# D1H.pdf register map
Vendor: Allwinner; Series: D1H.pdf; File version: 0.1
CPU: XuanTie C906 RISC-V CPU 0, little endian, MPU, FPU, double-precision FPU, 0 interrupt priority bits
Registers are 32-bit, read-write, reset 0x0 unless marked. A register's access mark holds for its fields unless they carry their own. Offsets are from the block's base; [hi:lo] are bit positions.

## USB1 (part 2 of 2)
Base 0x04200000
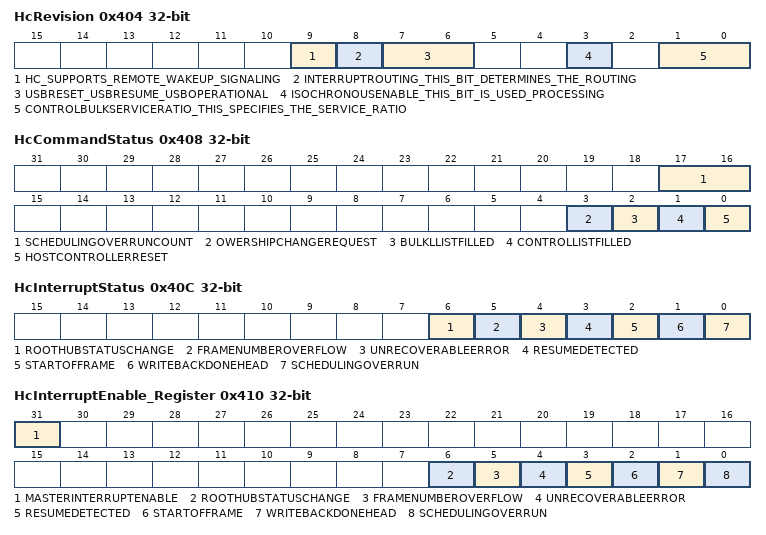
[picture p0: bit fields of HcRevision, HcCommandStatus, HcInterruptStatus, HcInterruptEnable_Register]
0x404 HcRevision (reset mask 0x53F)
  [9] HC_SUPPORTS_REMOTE_WAKEUP_SIGNALING — This bit indicates whether HC supports remote wakeup signaling. If remote wakeup is supported and used by the system, it is the responsibility of system firmware to set this bit during POST. HC clear the bit upon a hardware reset but does not alter it upon a software reset. Remote wakeup signaling of the host system is host-bus-specific and is not described in this specification.
  [8] INTERRUPTROUTING_THIS_BIT_DETERMINES_THE_ROUTING — InterruptRouting This bit determines the routing of interrupts generated by events registered in HcInterruptStatus. If clear, all interrupt are routed to the normal host bus interrupt mechanism. If set interrupts are routed to the System Management Interrupt. HCD clears this bit upon a hardware reset, but it does not alter this bit upon a software reset. HCD uses this bit as a tag to indicate the ownership of HC.
  [7:6] USBRESET_USBRESUME_USBOPERATIONAL — 00b USBReset 01b USBResume 10b USBOperational 11b USBSuspend A transition to USBOperational from another state causes SOF generation to begin 1 ms later. HCD may determine whether HC has begun sending SOFs by reading the StartoFrame field of HcInterruptStatus. This field may be changed by HC only when in the USBSUSPEND state. HC may move from the USBSUSPEND state to the USBRESUME state after detecting the resume signaling from a downstream port. HC enters USBSUSPEND after a software reset, whereas it enters USBRESET after a hardware reset. The latter also resets the Root Hub and asserts subsequent reset signaling to downstream ports.
  [3] ISOCHRONOUSENABLE_THIS_BIT_IS_USED_PROCESSING — IsochronousEnable This bit is used by HCD to enable/disable processing of isochronous EDs. While processing the periodic list in a Frame, HC checks the status of this bit when it finds an Isochronous ED (F=1). If set (enabled), HC continues processing the EDs. If cleared (disabled), HC halts processing of the periodic list (which now contains only isochronous EDs) and begins processing the Bulk/Control lists. Setting this bit is guaranteed to take effect in the next Frame (not the current Frame).
  [1:0] CONTROLBULKSERVICERATIO_THIS_SPECIFIES_THE_SERVICE_RATIO — ControlBulkServiceRatio This specifies the service ratio between Control and Bulk EDs. Before processing any of the nonperiodic lists, HC must compare the ratio specified with its internal count on how many nonempty Control EDs have been processed, in determining whether to continue serving another Control ED or switching to Bulk EDs. The internal count will be retained when crossing the frame boundary. In case of reset, HCD is responsible for restoring this value. CBSR No. of Control EDs Over Bulk EDs Served 0 1:1 1 2:1 2 3:1 3 4:1 The default value is 0x0.
0x408 HcCommandStatus
  [17:16] SCHEDULINGOVERRUNCOUNT ro — SchedulingOverrunCount These bits are incremented on each scheduling overrun error. It is initialized to 00b and wraps around at 11b. This will be incremented when a scheduling overrun is detected even if SchedulingOverrun in has already been set. This is used by HCD to monitor any persistent scheduling problem.
  [3] OWERSHIPCHANGEREQUEST — OwershipChangeRequest This bit is set by an OS HCD to request a change of control of the HC. When set HC will set the OwnershipChange field in . After the changeover, this bit is cleared and remains so until the next request from OS HCD.
  [2] BULKLLISTFILLED — BulklListFilled This bit is used to indicate whether there are any TDs on the Bulk list. It is set by HCD whenever it adds a TD to an ED in the Bulk list. When HC begins to process the head of the Bulk list, it checks BLF. As long as BulkListFilled is 0, HC will not start processing the Bulk list. If BulkListFilled is 1, HC will start processing the Bulk list and will set BF to 0. If HC finds a TD on the list, then HC will set BulkListFilled to 1 causing the Bulk list processing to continue. If no TD is found on the Bulk list, and if HCD does not set BulkListFilled , then BulkListFilled will still be 0 when HC completes processing the Bulk list and Bulk list processing will stop.
  [1] CONTROLLISTFILLED — ControlListFilled This bit is used to indicate whether there are any TDs on the Control list. It is set by HCD whenever it adds a TD to an ED in the Control list. When HC begins to process the head of the Control list, it checks CLF. As long as ControlListFilled is 0, HC will not start processing the Control list. If CF is 1, HC will start processing the Control list and will set ControlListFilled to 0. If HC finds a TD on the list, then HC will set ControlListFilled to 1 causing the Control list processing to continue. If no TD is found on the Control list, and if the HCD does not set ControlListFilled , then ControlListFilled will still be 0 when HC completes processing the Control list and Control list processing will stop.
  [0] HOSTCONTROLLERRESET — HostControllerReset This bit is by HCD to initiate a software reset of HC. Regardless of the functional state of HC, it moves to the USBSuspend state in which most of the operational registers are reset except those stated otherwise; e.g, the InteruptRouting field of HcControl, and no Host bus accesses are allowed. This bit is cleared by HC upon the completion of the reset operation. The reset operation must be completed within 10 ms. This bit, when set, should not cause a reset to the Root Hub and no subsequent reset signaling should be asserted to its downstream ports.
0x40C HcInterruptStatus
  [6] ROOTHUBSTATUSCHANGE — RootHubStatusChange This bit is set when the content of or the content of any of [ NumberofDownstreamPort ] has changed.
  [5] FRAMENUMBEROVERFLOW — FrameNumberOverflow This bit is set when the MSb of (bit 15) changes value, from 0 to 1 or from 1 to 0, and after has been updated.
  [4] UNRECOVERABLEERROR — UnrecoverableError This bit is set when HC detects a system error not related to USB. HC should not proceed with any processing nor signaling before the system error has been corrected. HCD clears this bit after HC has been reset.
  [3] RESUMEDETECTED — ResumeDetected This bit is set when HC detects that a device on the USB is asserting resume signaling. It is the transition from no resume signaling to resume signaling causing this bit to be set. This bit is not set when HCD sets the USBRseume state.
  [2] STARTOFFRAME — StartofFrame This bit is set by HC at each start of frame and after the update of HccaFrameNumber. HC also generates a SOF token at the same time.
  [1] WRITEBACKDONEHEAD — WritebackDoneHead This bit is set immediately after HC has written to . Further updates of the will not occur until this bit has been cleared. HCD should only clear this bit after it has saved the content of .
  [0] SCHEDULINGOVERRUN — SchedulingOverrun This bit is set when the USB schedule for the current Frame overruns and after the update of . A scheduling overrun will also cause the SchedulingOverrunCount of to be incremented.
0x410 HcInterruptEnable_Register
  [31] MASTERINTERRUPTENABLE — MasterInterruptEnable A ‘0’ writtern to this field is ignored by HC. A ‘1’ written to this field enables interrupt generation due to events specified in the other bits of this register. This is used by HCD as Master Interrupt Enable.
  [6] ROOTHUBSTATUSCHANGE — RootHubStatusChange Interrupt Enable 0 Ignore; 1 Enable interrupt generation due to Root Hub Status Change;
  [5] FRAMENUMBEROVERFLOW — FrameNumberOverflow Interrupt Enable 0 Ignore; 1 Enable interrupt generation due to Frame Number Over Flow;
  [4] UNRECOVERABLEERROR — UnrecoverableError Interrupt Enable 0 Ignore; 1 Enable interrupt generation due to Unrecoverable Error;
  [3] RESUMEDETECTED — ResumeDetected Interrupt Enable 0 Ignore; 1 Enable interrupt generation due to Resume Detected;
  [2] STARTOFFRAME — StartofFrame Interrupt Enable 0 Ignore; 1 Enable interrupt generation due to Start of Flame;
  [1] WRITEBACKDONEHEAD — WritebackDoneHead Interrupt Enable 0 Ignore; 1 Enable interrupt generation due to Write back Done Head;
  [0] SCHEDULINGOVERRUN — SchedulingOverrun Interrupt Enable 0 Ignore; 1 Enable interrupt generation due to Scheduling Overrun;
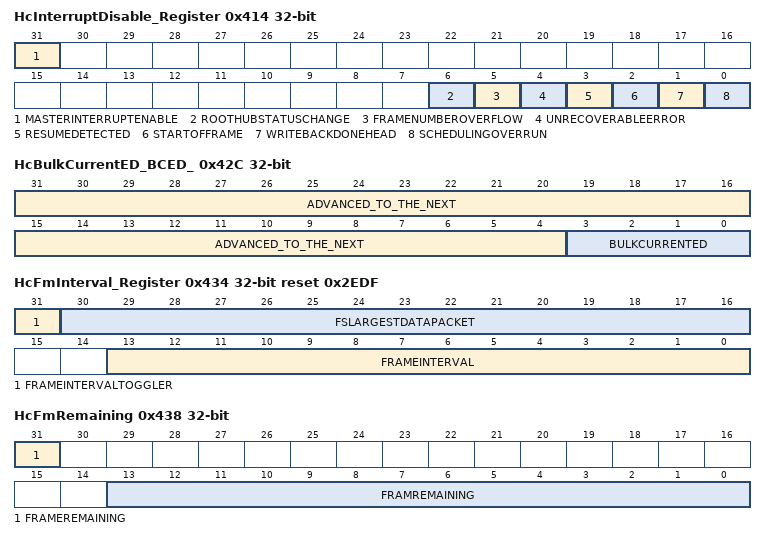
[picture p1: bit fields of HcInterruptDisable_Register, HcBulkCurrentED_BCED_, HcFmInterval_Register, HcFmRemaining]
0x414 HcInterruptDisable_Register
  [31] MASTERINTERRUPTENABLE — MasterInterruptEnable A written ‘0’ to this field is ignored by HC. A ‘1’ written to this field disables interrupt generation due events specified in the other bits of this register. This field is set after a hardware or software reset.
  [6] ROOTHUBSTATUSCHANGE — RootHubStatusChange Interrupt Disable 0 Ignore; 1 Disable interrupt generation due to Root Hub Status Change;
  [5] FRAMENUMBEROVERFLOW — FrameNumberOverflow Interrupt Disable 0 Ignore; 1 Disable interrupt generation due to Frame Number Over Flow;
  [4] UNRECOVERABLEERROR — UnrecoverableError Interrupt Disable 0 Ignore; 1 Disable interrupt generation due to Unrecoverable Error;
  [3] RESUMEDETECTED — ResumeDetected Interrupt Disable 0 Ignore; 1 Disable interrupt generation due to Resume Detected;
  [2] STARTOFFRAME — StartofFrame Interrupt Disable 0 Ignore; 1 Disable interrupt generation due to Start of Flame;
  [1] WRITEBACKDONEHEAD — WritebackDoneHead Interrupt Disable 0 Ignore; 1 Disable interrupt generation due to Write back Done Head;
  [0] SCHEDULINGOVERRUN — SchedulingOverrun Interrupt Disable 0 Ignore; 1 Disable interrupt generation due to Scheduling Overrun;
0x418 HcHCCA
0x41C HcPeriodCurrentED_PCED_
0x420 HcControlHeadED_CHED_
0x424 HcControlCurrentED_CCED_
0x428 HcBulkHeadED_BHED_
0x42C HcBulkCurrentED_BCED_ (reset mask 0xF)
  [31:4] ADVANCED_TO_THE_NEXT — This is advanced to the next ED after the HC has served the present one. HC continues processing the list from where it left off in the last Frame. When it reaches the end of the Bulk list, HC checks the ControlListFilled of HcControl. If set, it copies the content of to and clears the bit. If it is not set, it does nothing. HCD is only allowed to modify this register when the BulkListEnable of is cleared. When set, the HCD only reads the instantaneous value of this register. This is initially set to zero to indicate the end of the Bulk list.
  [3:0] BULKCURRENTED ro — BulkCurrentED [3:0] Because the general TD length is 16 bytes, the memory structure for the TD must be aligned to a 16-byte boundary. So the lower bits in the PCED, through bit 0 to bit 3 must be zero in this field.
0x430 HcDoneHead
0x434 HcFmInterval_Register reset 0x2EDF
  [31] FRAMEINTERVALTOGGLER — FrameIntervalToggler HCD toggles this bit whenever it loads a new value to FrameInterval .
  [30:16] FSLARGESTDATAPACKET — FSLargestDataPacket This field specifies a value which is loaded into the Largest Data Packet Counter at the beginning of each frame. The counter value represents the largest amount of data in bits which can be sent or received by the HC in a single transaction at any given time without causing scheduling overrun. The field value is calculated by the HCD.
  [13:0] FRAMEINTERVAL — FrameInterval This specifies the interval between two consecutive SOFs in bit times. The nominal value is set to be 11,999. HCD should store the current value of this field before resetting HC. By setting the HostControllerReset field of as this will cause the HC to reset this field to its nominal value. HCD may choose to restore the stored value upon the completion of the Reset sequence.
0x438 HcFmRemaining
  [31] FRAMEREMAINING ro — FrameRemaining Toggle This bit is loaded from the FrameIntervalToggle field of whenever FrameRemaining reaches 0. This bit is used by HCD for the synchronization between FrameInterval and FrameRemaining .
  [13:0] FRAMREMAINING ro — FramRemaining This counter is decremented at each bit time. When it reaches zero, it is reset by loading the FrameInterval value specified in at the next bit time boundary. When entering the USBOPERATIONAL state, HC re-loads the content with the FrameInterval of and uses the updated value from the next SOF.
0x43C HcFmNumber
  [15:0] FRAMENUMBER ro — FrameNumber This is incremented when is re-loaded. It will be rolled over to 0x0 after 0x0ffff. When entering the USBOPERATIONAL state, this will be incremented automatically. The content will be written to HCCA after HC has incremented the FrameNumber at each frame boundary and sent a SOF but before HC reads the first ED in that Frame. After writing to HCCA, HC will set the StartofFrame in
0x440 HcPeriodicStatus
  [13:0] PERIODICSTART — PeriodicStart After a hardware reset, this field is cleared. This is then set by HCD during the HC initialization. The value is calculated roughly as 10% off from . A typical value will be 0x2A3F (or 0x3e67). When reaches the value specified, processing of the periodic lists will have priority over Control/Bulk processing. HC will therefore start processing the Interrupt list after completing the current Control or Bulk transaction that is in progress.
0x444 HcLSThreshold reset 0x628
  [11:0] LSTHRESHOLD — LSThreshold This field contains a value which is compared to the FrameRemaining field prior to initiating a Low Speed transaction. The transaction is started only if FrameRemaining this field. The value is calculated by HCD with the consideration of transmission and setup overhead.
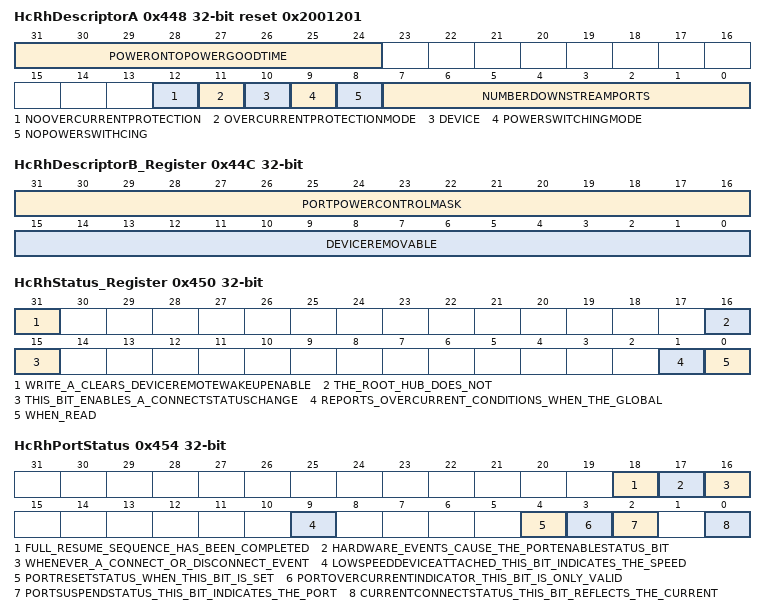
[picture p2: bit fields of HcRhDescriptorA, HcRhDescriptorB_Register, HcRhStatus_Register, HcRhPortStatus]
0x448 HcRhDescriptorA reset 0x2001201
  [31:24] POWERONTOPOWERGOODTIME — PowerOnToPowerGoodTime[POTPGT] This byte specifies the duration HCD has to wait before accessing a powered-on port of the Root Hub. It is implementation-specific. The unit of time is 2 ms. The duration is calculated as POTPGT * 2ms.
  [12] NOOVERCURRENTPROTECTION — NoOverCurrentProtection This bit describes how the overcurrent status for the Root Hub ports are reported. When this bit is cleared, the OverCurrentProtectionMode field specifies global or per-port reporting. 0 Over-current status is reported collectively for all downstream ports. 1 No overcurrent protection supported.
  [11] OVERCURRENTPROTECTIONMODE — OverCurrentProtectionMode This bit describes how the overcurrent status for the Root Hub ports are reported. At reset, these fields should reflect the same mode as PowerSwitchingMode . This field is valid only if the NoOverCurrentProtection field is cleared. 0 Over-current status is reported collectively for all downstream ports. 1 Over-current status is reported on per-port basis.
  [10] DEVICE ro — Device Type This bit specifies that the Root Hub is not a compound device. The Root Hub is not permitted to be a compound device. This field should always read/write 0.
  [9] POWERSWITCHINGMODE — PowerSwitchingMode This bit is used to specify how the power switching of the Root Hub ports is controlled. It is implementation-specific. This field is only valid if the NoPowerSwitching field is cleared. 0 All ports are powered at the same time. 1 Each port is powered individually. This mode allows port power to be controlled by either the global switch or per- port switching. If the PortPowerControlMask bit is set, the port responds only to port power commands ( Set/ClearPortPower ). If the port mask is cleared, then the port is controlled only by the global power switch ( Set/ClearGlobalPower ).
  [8] NOPOWERSWITHCING — NoPowerSwithcing These bits are used to specify whether power switching is supported or ports are always powered. It is implementation- specific. When this bit is cleared, the PowerSwitchingMode specifies global or per-port switching. 0 Ports are power switched. 1 Ports are always powered on when the HC is powered on.
  [7:0] NUMBERDOWNSTREAMPORTS ro — NumberDownstreamPorts These bits specify the number of downstream ports supported by the Root Hub. It is implementation-specific. The minimum number of ports is 1. The maximum number of ports supported.
0x44C HcRhDescriptorB_Register
  [31:16] PORTPOWERCONTROLMASK — PortPowerControlMask Each bit indicates if a port is affected by a global power control command when PowerSwitchingMode is set. When set, the port's power state is only affected by per-port power control ( Set/ClearPortPower ). When cleared, the port is controlled by the global power switch ( Set/ClearGlobalPower ). If the device is configured to global switching mode ( PowerSwitchingMode = 0 ), this field is not valid. Bit0 Reserved Bit1 Ganged-power mask on Port #1. Bit2 Ganged-power mask on Port #2. … Bit15 Ganged-power mask on Port #15.
  [15:0] DEVICEREMOVABLE — DeviceRemovable Each bit is dedicated to a port of the Root Hub. When cleared, the attached device is removable. When set, the attached device is not removable. Bit0 Reserved Bit1 Device attached to Port #1. Bit2 Device attached to Port #2. … Bit15 Device attached to Port #15.
0x450 HcRhStatus_Register (reset mask 0x80038001)
  [31] WRITE_A_CLEARS_DEVICEREMOTEWAKEUPENABLE wo — (write)ClearRemoteWakeupEnable Write a ‘1’ clears DeviceRemoteWakeupEnable. Writing a ‘0’ has no effect.
  [16] THE_ROOT_HUB_DOES_NOT — (read)LocalPowerStartusChange The Root Hub does not support the local power status features, thus, this bit is always read as ‘0’. (write)SetGlobalPower In global power mode ( PowerSwitchingMode =0), This bit is written to ‘1’ to turn on power to all ports (clear PortPowerStatus ). In per-port power mode, it sets PortPowerStatus only on ports whose PortPowerControlMask bit is not set. Writing a ‘0’ has no effect.
  [15] THIS_BIT_ENABLES_A_CONNECTSTATUSCHANGE — (read)DeviceRemoteWakeupEnable This bit enables a ConnectStatusChange bit as a resume event, causing a USBSUSPEND to USBRESUME state transition and setting the ResumeDetected interrupt. 0 ConnectStatusChange is not a remote wakeup event. 1 ConnectStatusChange is a remote wakeup event. (write)SetRemoteWakeupEnable Writing a ‘1’ sets DeviceRemoveWakeupEnable. Writing a ‘0’ has no effect.
  [1] REPORTS_OVERCURRENT_CONDITIONS_WHEN_THE_GLOBAL ro — This bit reports overcurrent conditions when the global reporting is implemented. When set, an overcurrent condition exists. When cleared, all power operations are normal. If per-port overcurrent protection is implemented this bit is always ‘0’
  [0] WHEN_READ — (Read)LocalPowerStatus When read, this bit returns the LocalPowerStatus of the Root Hub. The Root Hub does not support the local power status feature; thus, this bit is always read as ‘0’. (Write)ClearGlobalPower When write, this bit is operated as the ClearGlobalPower. In global power mode ( PowerSwitchingMode =0), This bit is written to ‘1’ to turn off power to all ports (clear PortPowerStatus ). In per-port power mode, it clears PortPowerStatus only on ports whose PortPowerControlMask bit is not set. Writing a ‘0’ has no effect.
0x454 HcRhPortStatus reset not defined
  [18] FULL_RESUME_SEQUENCE_HAS_BEEN_COMPLETED — This bit is set when the full resume sequence has been completed. This sequence includes the 20-s resume pulse, LS EOP, and 3-ms resychronization delay. The HCD writes a ‘1’ to clear this bit. Writing a ‘0’ has no effect. This bit is also cleared when ResetStatusChange is set. 0 resume is not completed 1 resume completed
  [17] HARDWARE_EVENTS_CAUSE_THE_PORTENABLESTATUS_BIT — This bit is set when hardware events cause the PortEnableStatus bit to be cleared. Changes from HCD writes do not set this bit. The HCD writes a ‘1’ to clear this bit. Writing a ‘0’ has no effect. 0 no change in PortEnableStatus 1 change in PortEnableStatus
  [16] WHENEVER_A_CONNECT_OR_DISCONNECT_EVENT — This bit is set whenever a connect or disconnect event occurs. The HCD writes a ‘1’ to clear this bit. Writing a ‘0’ has no effect. If CurrentConnectStatus is cleared when a SetPortReset,SetPortEnable , or SetPortSuspend write occurs, this bit is set to force the driver to re-evaluate the connection status since these writes should not occur if the port is disconnected. 0 no change in PortEnableStatus 1 change in PortEnableStatus Note: If the DeviceRemovable[NDP] bit is set, this bit is set only after a Root Hub reset to inform the system that the device is attached.
  [9] LOWSPEEDDEVICEATTACHED_THIS_BIT_INDICATES_THE_SPEED — LowSpeedDeviceAttached This bit indicates the speed of the device attached to this port. When set, a Low Speed device is attached to this port. When clear, a Full Speed device is attached to this port. This field is valid only when the CurrentConnectStatus is set. 0 full speed device attached 1 low speed device attached (write) ClearPortPower The HCD clears the PortPowerStatus bit by writing a ‘1’ to this bit. Writing a ‘0’ has no effect.
  [4] PORTRESETSTATUS_WHEN_THIS_BIT_IS_SET — PortResetStatus When this bit is set by a write to SetPortReset , port reset signaling is asserted. When reset is completed, this bit is cleared when PortResetStatusChange is set. This bit cannot be set if CurrentConnectStatus is cleared. 0 port reset signal is not active 1 port reset signal is active (write) SetPortReset The HCD sets the port reset signaling by writing a ‘1’ to this bit. Writing a ‘0’ has no effect. If CurrentConnectStatus is cleared, this write does not set PortResetStatus , but instead sets ConnectStatusChange . This informs the driver that it attempted to reset a disconnected port.
  [3] PORTOVERCURRENTINDICATOR_THIS_BIT_IS_ONLY_VALID — PortOverCurrentIndicator This bit is only valid when the Root Hub is configured in such a way that overcurrent conditions are reported on a per-port basis. If per-port overcurrent reporting is not supported, this bit is set to 0. If cleared, all power operations are normal for this port. If set, an overcurrent condition exists on this port. This bit always reflects the overcurrent input signal. 0 no overcurrent condition. 1 overcurrent condition detected. (write) ClearSuspendStatus The HCD writes a ‘1’ to initiate a resume. Writing a ‘0’ has no effect. A resume is initiated only if PortSuspendStatus is set.
  [2] PORTSUSPENDSTATUS_THIS_BIT_INDICATES_THE_PORT — PortSuspendStatus This bit indicates the port is suspended or in the resume sequence. It is set by a SetSuspendState write and cleared when PortSuspendStatusChange is set at the end of the resume interval. This bit cannot be set if CurrentConnectStatus is cleared. This bit is also cleared when PortResetStatusChange is set at the end of the port reset or when the HC is placed in the USBRESUME state. If an upstream resume is in progress, it should propagate to the HC. 0 port is not suspended 1 port is suspended (write) SetPortSuspend The HCD sets the PortSuspendStatus bit by writing a ‘1’ to this bit. Writing a ‘0’ has no effect. If CurrentConnectStatus is cleared, this write does not set PortSuspendStatus ; instead it sets ConnectStatusChange . This informs the driver that it attempted to suspend a disconnected port.
  [0] CURRENTCONNECTSTATUS_THIS_BIT_REFLECTS_THE_CURRENT — CurrentConnectStatus This bit reflects the current state of the downstream port. 0 No device connected 1 Device connected (write) ClearPortEnable The HCD writes a ‘1’ to clear the PortEnableStatus bit. Writing ‘0’ to this bit has no effect. The CurrentConnectStatus is not affected by any write. Note: This bit is always read ‘1’ when the attached device is nonremovalble (DviceRemoveable[NumberDownstreamPort]).
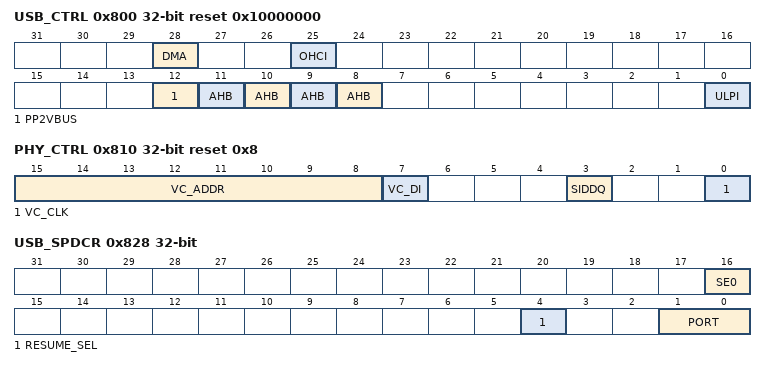
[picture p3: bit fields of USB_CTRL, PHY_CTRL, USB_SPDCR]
0x800 USB_CTRL reset 0x10000000
  [28] DMA ro — Transfer Status Enable 0: Disable 1: Enable
    0=Disable; 1=Enable
  [25] OHCI — count select 1: Simulation mode. The counters will be much shorter then real time 0: Normal mode. The counters will count full time
    1=Simulation mode. The counters will be much shorter then real time; 0=Normal mode. The counters will count full time
  [12] PP2VBUS — 1: ULPI wrapper interface will automatically set or clear DrvVbus register in ULPI PHY according to the port power status form the root hub 0: ULPI wrapper will ignore the difference between power status of root hub and ULPI PHY
    1=ULPI wrapper interface will automatically set or clear DrvVbus register in ULPI PHY according to the port power status form the root hub; 0=ULPI wrapper will ignore the difference between power status of root hub and ULPI PHY
  [11] AHB — Master interface INCR16 enable 1: Use INCR16 when appropriate 0: Do not use INCR16, use other enabled INCRX or unspecified length burst INCR
    1=Use INCR16 when appropriate; 0=Do not use INCR16, use other enabled INCRX or unspecified length burst INCR
  [10] AHB — Master interface INCR8 enable 1: Use INCR8 when appropriate 0: Do not use INCR8, use other enabled INCRX or unspecified length burst INCR
    1=Use INCR8 when appropriate; 0=Do not use INCR8, use other enabled INCRX or unspecified length burst INCR
  [9] AHB — Master interface burst type INCR4 enable 1: Use INCR4 when appropriate 0: Do not use INCR4, use other enabled INCRX or unspecified length burst INCR
    1=Use INCR4 when appropriate; 0=Do not use INCR4, use other enabled INCRX or unspecified length burst INCR
  [8] AHB — Master interface INCRX align enable 1: Start INCRx burst only on burst x-align address 0: Start burst on any double word boundary Note: This bit must enable if any bit of bit[11:9] is enabled
    1=Start INCRx burst only on burst x-align address; 0=Start burst on any double word boundary Note: This bit must enable if any bit of bit[11:9] is enabled
  [0] ULPI — bypass enable 1: Enable UTMI interface, disable ULPI interface 0: Enable ULPI interface, disable UTMI interface
    1=Enable UTMI interface, disable ULPI interface; 0=Enable ULPI interface, disable UTMI interface
0x810 PHY_CTRL reset 0x8
  [15:8] VC_ADDR
  [7] VC_DI
  [3] SIDDQ — 1: Write 1 to disable phy 0: Write 0 to enable phy
    1=Write 1 to disable phy; 0=Write 0 to enable phy
  [0] VC_CLK
0x828 USB_SPDCR
  [16] SE0 — Status This bit is set when no-se0 is detected before SOF when bit[1:0] is 10b or 11b
  [4] RESUME_SEL — resume_sel When set k-se0 transition 2 us, setting this bit to 1, which is cooperated with ss_utmi_backward_enb_i.
  [1:0] PORT — Port Disable Control 00: Port Disable when no-se0 detect before SOF 01: Port Disable when no-se0 detect before SOF 10: No Port Disable when no-se0 detect before SOF 11: Port Disable when no-se0 3 time detect before SOF during 8 frames
